# STM32L412C8T6 register map
File version: 1.0
Registers are 32-bit, access not given, reset 0x0 unless marked. A register's access mark holds for its fields unless they carry their own. Offsets are from the block's base; [hi:lo] are bit positions; {n}, {i} and the like mark numbered series.

## I2C1
Base 0x40005400
Same registers: I2C2 0x40005800, I2C3 0x40005C00, I2C4 0x40008400
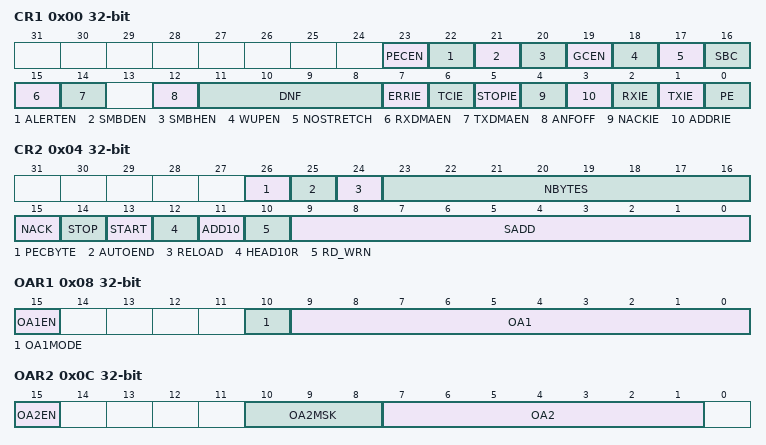
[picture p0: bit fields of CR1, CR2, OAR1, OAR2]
0x00 CR1
  [23] PECEN, [22] ALERTEN, [21] SMBDEN, [20] SMBHEN, [19] GCEN, [18] WUPEN, [17] NOSTRETCH, [16] SBC, [15] RXDMAEN, [14] TXDMAEN, [12] ANFOFF, [11:8] DNF, [7] ERRIE, [6] TCIE, [5] STOPIE, [4] NACKIE, [3] ADDRIE, [2] RXIE, [1] TXIE, [0] PE
0x04 CR2
  [26] PECBYTE, [25] AUTOEND, [24] RELOAD, [23:16] NBYTES, [15] NACK, [14] STOP, [13] START, [12] HEAD10R, [11] ADD10, [10] RD_WRN, [9:0] SADD
0x08 OAR1
  [15] OA1EN, [10] OA1MODE, [9:0] OA1
0x0C OAR2
  [15] OA2EN, [10:8] OA2MSK, [7:1] OA2
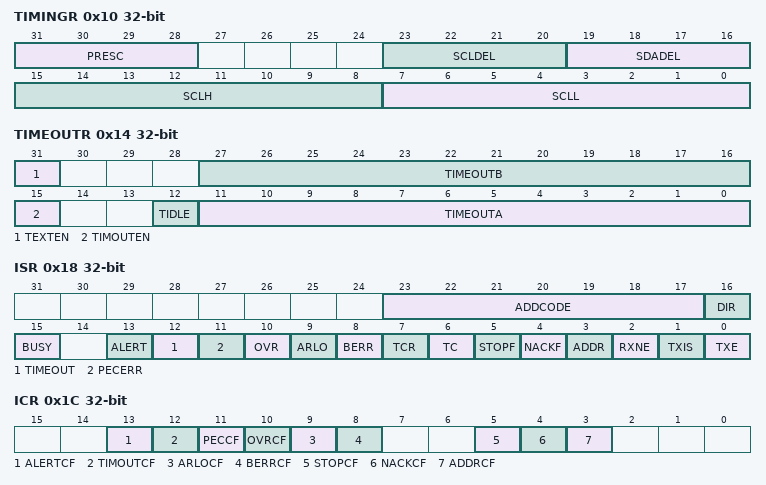
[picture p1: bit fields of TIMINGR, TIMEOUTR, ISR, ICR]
0x10 TIMINGR
  [31:28] PRESC, [23:20] SCLDEL, [19:16] SDADEL, [15:8] SCLH, [7:0] SCLL
0x14 TIMEOUTR
  [31] TEXTEN, [27:16] TIMEOUTB, [15] TIMOUTEN, [12] TIDLE, [11:0] TIMEOUTA
0x18 ISR
  [23:17] ADDCODE, [16] DIR, [15] BUSY, [13] ALERT, [12] TIMEOUT, [11] PECERR, [10] OVR, [9] ARLO, [8] BERR, [7] TCR, [6] TC, [5] STOPF, [4] NACKF, [3] ADDR, [2] RXNE, [1] TXIS, [0] TXE
0x1C ICR
  [13] ALERTCF, [12] TIMOUTCF, [11] PECCF, [10] OVRCF, [9] ARLOCF, [8] BERRCF, [5] STOPCF, [4] NACKCF, [3] ADDRCF
0x20 PECR
  [7:0] PEC
0x24 RXDR
  [7:0] RXDATA
0x28 TXDR
  [7:0] TXDATA

## CRS
Base 0x40006000
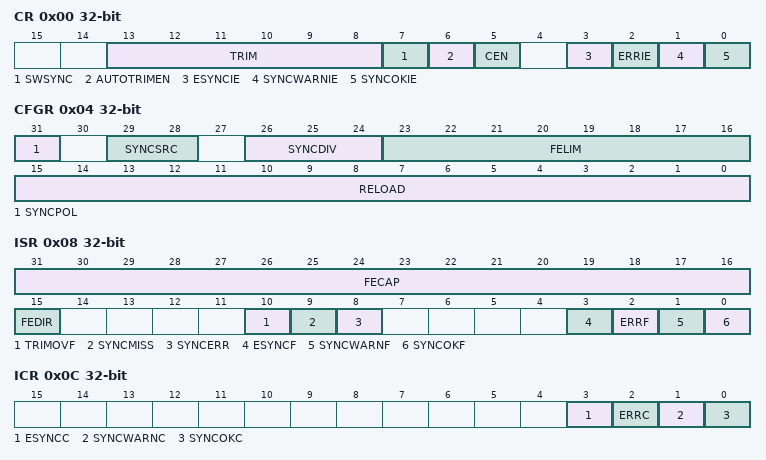
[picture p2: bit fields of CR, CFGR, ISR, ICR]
0x00 CR
  [13:8] TRIM, [7] SWSYNC, [6] AUTOTRIMEN, [5] CEN, [3] ESYNCIE, [2] ERRIE, [1] SYNCWARNIE, [0] SYNCOKIE
0x04 CFGR
  [31] SYNCPOL, [29:28] SYNCSRC, [26:24] SYNCDIV, [23:16] FELIM, [15:0] RELOAD
0x08 ISR
  [31:16] FECAP, [15] FEDIR, [10] TRIMOVF, [9] SYNCMISS, [8] SYNCERR, [3] ESYNCF, [2] ERRF, [1] SYNCWARNF, [0] SYNCOKF
0x0C ICR
  [3] ESYNCC, [2] ERRC, [1] SYNCWARNC, [0] SYNCOKC

## CAN1
Base 0x40006400
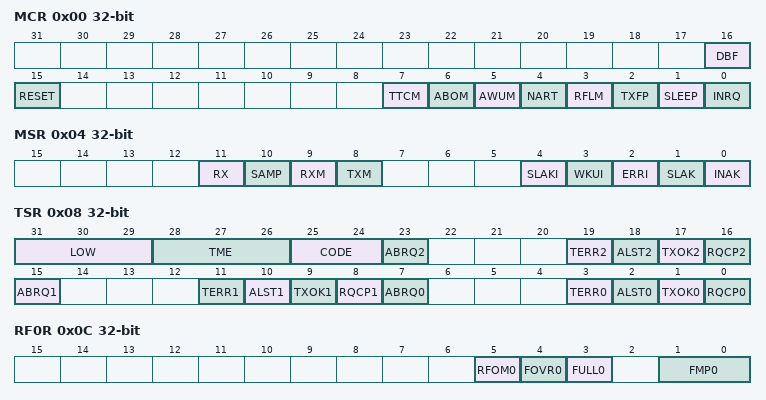
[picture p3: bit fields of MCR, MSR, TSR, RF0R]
0x00 MCR
  [16] DBF, [15] RESET, [7] TTCM, [6] ABOM, [5] AWUM, [4] NART, [3] RFLM, [2] TXFP, [1] SLEEP, [0] INRQ
0x04 MSR
  [11] RX, [10] SAMP, [9] RXM, [8] TXM, [4] SLAKI, [3] WKUI, [2] ERRI, [1] SLAK, [0] INAK
0x08 TSR
  [31:29] LOW, [28:26] TME, [25:24] CODE, [23] ABRQ2, [19] TERR2, [18] ALST2, [17] TXOK2, [16] RQCP2, [15] ABRQ1, [11] TERR1, [10] ALST1, [9] TXOK1, [8] RQCP1, [7] ABRQ0, [3] TERR0, [2] ALST0, [1] TXOK0, [0] RQCP0
0x0C RF0R
  [5] RFOM0, [4] FOVR0, [3] FULL0, [1:0] FMP0
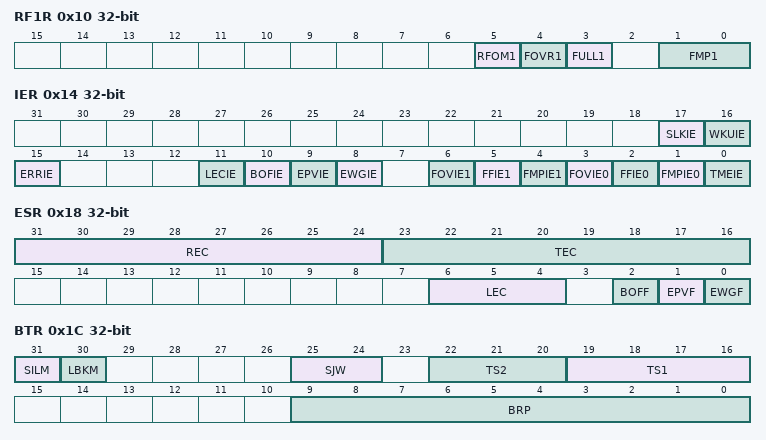
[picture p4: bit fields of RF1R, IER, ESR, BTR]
0x10 RF1R
  [5] RFOM1, [4] FOVR1, [3] FULL1, [1:0] FMP1
0x14 IER
  [17] SLKIE, [16] WKUIE, [15] ERRIE, [11] LECIE, [10] BOFIE, [9] EPVIE, [8] EWGIE, [6] FOVIE1, [5] FFIE1, [4] FMPIE1, [3] FOVIE0, [2] FFIE0, [1] FMPIE0, [0] TMEIE
0x18 ESR
  [31:24] REC, [23:16] TEC, [6:4] LEC, [2] BOFF, [1] EPVF, [0] EWGF
0x1C BTR
  [31] SILM, [30] LBKM, [25:24] SJW, [22:20] TS2, [19:16] TS1, [9:0] BRP
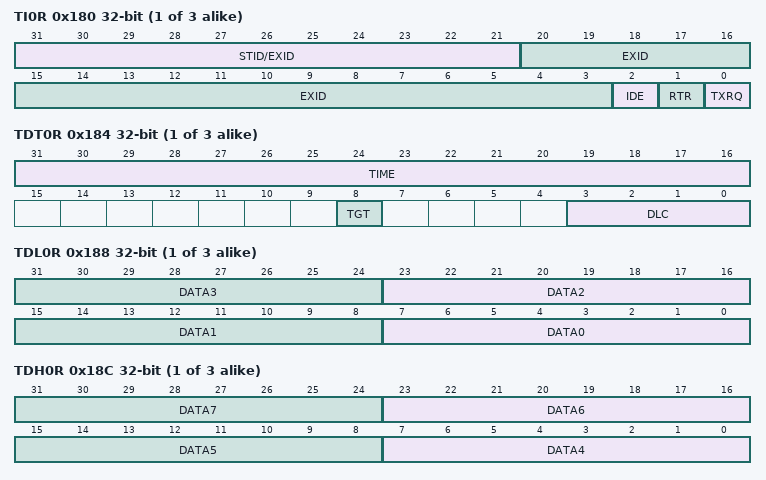
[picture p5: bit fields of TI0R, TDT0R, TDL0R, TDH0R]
{0x180+0x10*i} TI{i}R (i=0..2)
  [31:21] STID/EXID, [20:3] EXID, [2] IDE, [1] RTR, [0] TXRQ
{0x184+0x10*i} TDT{i}R (i=0..2)
  [31:16] TIME, [8] TGT, [3:0] DLC
{0x188+0x10*i} TDL{i}R (i=0..2)
  [8n+7:8n] DATA{n} (n=0..3)
{0x18C+0x10*i} TDH{i}R (i=0..2)
  [8n-25:8n-32] DATA{n} (n=4..7)
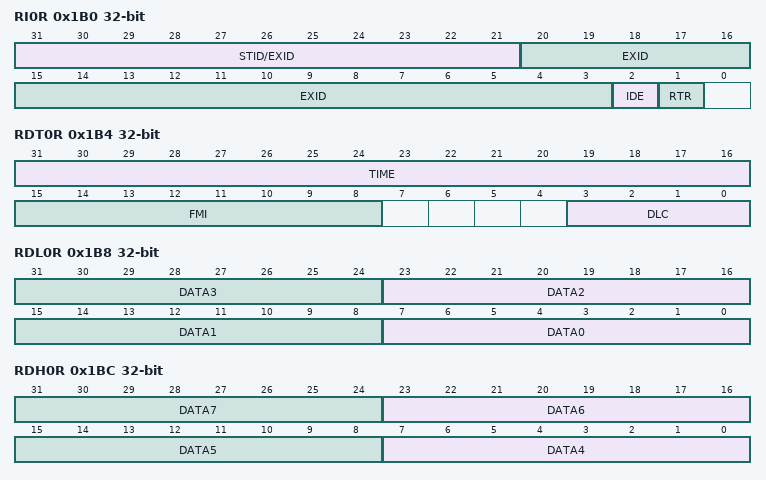
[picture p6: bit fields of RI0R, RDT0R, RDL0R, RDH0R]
0x1B0 RI0R
  [31:21] STID/EXID, [20:3] EXID, [2] IDE, [1] RTR
0x1B4 RDT0R
  [31:16] TIME, [15:8] FMI, [3:0] DLC
0x1B8 RDL0R
  [8n+7:8n] DATA{n} (n=0..3)
0x1BC RDH0R
  [8n-25:8n-32] DATA{n} (n=4..7)
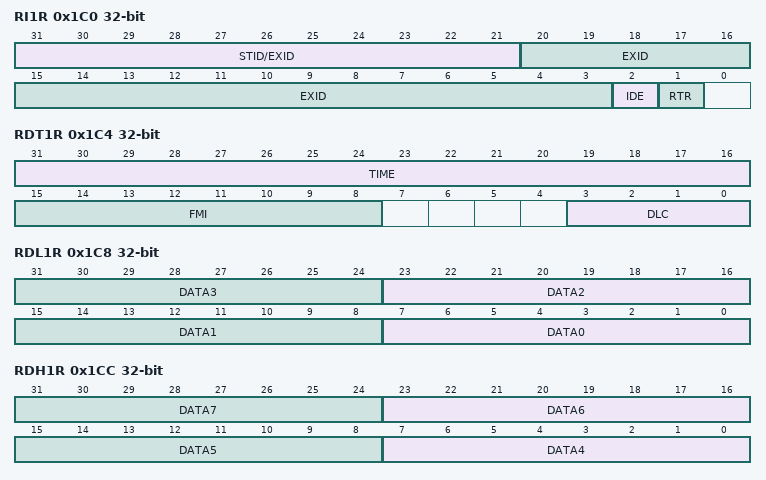
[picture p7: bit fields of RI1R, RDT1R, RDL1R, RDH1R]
0x1C0 RI1R
  [31:21] STID/EXID, [20:3] EXID, [2] IDE, [1] RTR
0x1C4 RDT1R
  [31:16] TIME, [15:8] FMI, [3:0] DLC
0x1C8 RDL1R
  [8n+7:8n] DATA{n} (n=0..3)
0x1CC RDH1R
  [8n-25:8n-32] DATA{n} (n=4..7)
0x200 FMR
  [0] FINIT
0x204 FM1R
  [13:0] FBM
0x20C FS1R
  [13:0] FSC
0x214 FFA1R
  [13:0] FFA
0x21C FA1R
  [13:0] FACT
{0x240+8i} F{i}R1 (i=0..27)
  [31:0] FB
{0x244+8i} F{i}R2 (i=0..27)
  [31:0] FB

## USBFS
Base 0x40006800
Same registers: USBSRAM 0x40006C00
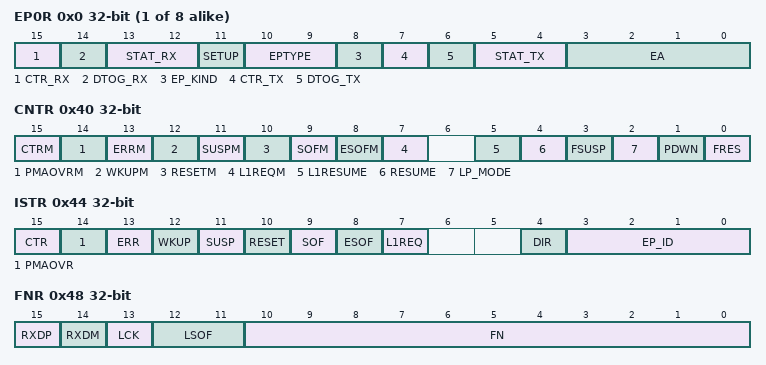
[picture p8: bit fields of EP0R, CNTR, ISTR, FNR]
{0x0+4i} EP{i}R (i=0..7)
  [15] CTR_RX, [14] DTOG_RX, [13:12] STAT_RX, [11] SETUP, [10:9] EPTYPE, [8] EP_KIND, [7] CTR_TX, [6] DTOG_TX, [5:4] STAT_TX, [3:0] EA
0x40 CNTR
  [15] CTRM, [14] PMAOVRM, [13] ERRM, [12] WKUPM, [11] SUSPM, [10] RESETM, [9] SOFM, [8] ESOFM, [7] L1REQM, [5] L1RESUME, [4] RESUME, [3] FSUSP, [2] LP_MODE, [1] PDWN, [0] FRES
0x44 ISTR
  [15] CTR, [14] PMAOVR, [13] ERR, [12] WKUP, [11] SUSP, [10] RESET, [9] SOF, [8] ESOF, [7] L1REQ, [4] DIR, [3:0] EP_ID
0x48 FNR
  [15] RXDP, [14] RXDM, [13] LCK, [12:11] LSOF, [10:0] FN
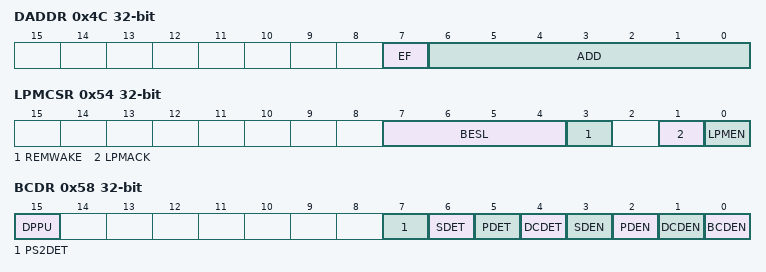
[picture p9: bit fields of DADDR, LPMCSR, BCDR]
0x4C DADDR
  [7] EF, [6:0] ADD
0x50 BTABLE
  [15:3] BTABLE
0x54 LPMCSR
  [7:4] BESL, [3] REMWAKE, [1] LPMACK, [0] LPMEN
0x58 BCDR
  [15] DPPU, [7] PS2DET, [6] SDET, [5] PDET, [4] DCDET, [3] SDEN, [2] PDEN, [1] DCDEN, [0] BCDEN
